# MINI51XAE_v1 register map
File version: 1.0
Registers are 32-bit, read-write, reset 0x0 unless marked. A register's access mark holds for its fields unless they carry their own. Offsets are from the block's base; [hi:lo] are bit positions; {n}, {i} and the like mark numbered series; 'fields as' and 'values as' point back to an identical list.

## PWM — PWM Register Map
Base 0x40040000
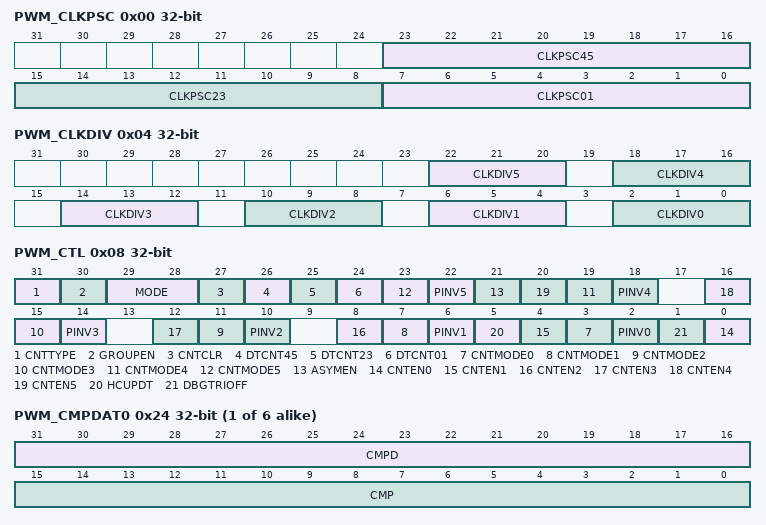
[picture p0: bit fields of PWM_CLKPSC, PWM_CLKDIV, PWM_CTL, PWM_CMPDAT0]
0x00 PWM_CLKPSC — PWM Pre-scale Register
  [23:16] CLKPSC45 — Clock Prescaler 4 For PWM Counter 4 And 5. Clock input is divided by (CLKPSC45 + 1) before it is fed to the corresponding PWM counter.
  [15:8] CLKPSC23 — Clock Prescaler 2 For PWM Counter 2 And 3. Clock input is divided by (CLKPSC23 + 1) before it is fed to the corresponding PWM counter.
  [7:0] CLKPSC01 — Clock Prescaler 0 For PWM Counter 0 And 1. Clock input is divided by (CLKPSC01 + 1) before it is fed to the corresponding PWM counter.
0x04 PWM_CLKDIV — PWM Clock Select Register
  [22:20] CLKDIV5 — Timer 5 Clock Source Selection. Select clock input for PWM timer.
    0=2 clock input/CLKPSC45/2; 1=4 clock input/CLKPSC45/4; 3=8 clock input/CLKPSC45/8; 4=16 clock input/CLKPSC45/16; 5=1 clock input/CLKPSC45/1; 6=Clock input
  [4n+2:4n] CLKDIV{n} (n=0..4) — Timer {n} Clock Source Selection. Select clock input for PWM timer. (Table is the same as CLKDIV5.)
0x08 PWM_CTL — PWM Control Register
  [31] CNTTYPE — PWM Aligned Type Selection Bit
    0=Edge-aligned type; 1=Center-aligned type
  [30] GROUPEN — Group Bit
    0=The signals timing of all PWM channels are independent; 1=Unify the signals timing of PWM0, PWM2 and PWM4 in the same phase which is controlled by PWM0 and also unify the signals timing of PWM1, PWM3 and PWM5 in the same phase which is controlled by PWM1
  [29:28] MODE — PWM Operating Mode Selection
    0=Independent mode; 1=Complementary mode; 2=Synchronized mode
  [27] CNTCLR — Clear PWM Counter Control Bit. Note: It is automatically cleared by hardware.
    0=Do not clear PWM counter; 1=All 16-bit PWM counters cleared to 0x0000
  [26] DTCNT45 — Dead-Zone 4 Generator Enable/Disable (PWM4 And PWM5 Pair For PWM Group). Note: When the dead-zone generator is enabled, the pair of PWM4 and PWM5 becomes a complementary pair for PWM group.
    0=Disabled; 1=Enabled
  [25] DTCNT23 — Dead-Zone 2 Generator Enable/Disable (PWM2 And PWM3 Pair For PWM Group). Note: When the dead-zone generator is enabled, the pair of PWM2 and PWM3 becomes a complementary pair for PWM group.
    0=Disabled; 1=Enabled
  [24] DTCNT01 — Dead-Zone 0 Generator Enable/Disable (PWM0 And PWM1 Pair For PWM Group). Note: When the dead-zone generator is enabled, the pair of PWM0 and PWM1 becomes a complementary pair for PWM group.
    0=Disabled; 1=Enabled
  [4n+3] CNTMODE{n} (n=0..5) — PWM-Timer {n} Auto-Reload/One-Shot Mode. Note: If there is a rising transition at this bit, it will cause PWM_PERIOD{n} and PWM_CMPDAT{n} cleared.
    0=One-shot mode; 1=Auto-reload mode
  [4n+2] PINV{n} (n=0..5) — PWM-Timer {n} Output Inverter Enabled/Disabled
    0=Inverter Disabled; 1=Inverter Enabled
  [21] ASYMEN — Asymmetric Mode In Center-Aligned Type
    0=symmetric mode in center-aligned type; 1=asymmetric mode in center-aligned type
  [4n] CNTEN{n} (n=0..5) — PWM-Timer {n} Enable/Disable Start Run
    0=Corresponding PWM-timer running Stopped; 1=Corresponding PWM-timer start run Enabled
  [5] HCUPDT — Half Cycle Update Enable For Center-Aligned Type
    0=disable half cycle update PERIOD CMP; 1=enable half cycle update PERIOD CMP
  [1] DBGTRIOFF — PWM Debug Mode Configuration Bit (Available In DEBUG Mode Only)
    0=Safe mode: The timer is frozen and PWM outputs are shut down Safe state for the inverter. The timer can still be re-started from where it stops; 1=Normal mode: The timer continues to operate normally May be dangerous in some cases since a constant duty cycle is applied to the inverter (no more interrupts serviced)
{0xC+4i} PWM_PERIOD{i} (i=0..5) — PWM Counter Register {i}
  [15:0] PERIOD — PWM Counter/Timer Loaded Value. PERIOD determines the PWM period. Edge-aligned mode: Note: Any write to PERIOD will take effect in next PWM cycle.
{0x24+4i} PWM_CMPDAT{i} (i=0..5) — PWM Comparator Register {i}
  [31:16] CMPD — PWM Comparator Register For Down Counter In Center-Aligned Asymmetric Mode. Others: PWM output is always high
  [15:0] CMP — PWM Comparator Register. CMP determines the PWM duty. Edge-aligned mode: Note: Any write to CMP will take effect in next PWM cycle.
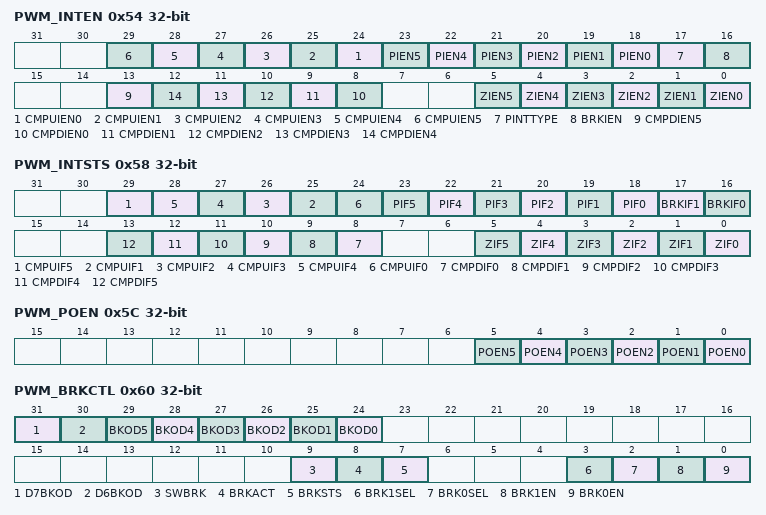
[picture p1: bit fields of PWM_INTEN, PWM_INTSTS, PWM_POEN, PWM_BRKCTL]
0x54 PWM_INTEN — PWM Interrupt Enable Register
  [n+24] CMPUIEN{n} (n=0..5) — PWM Channel {n} Rising Interrupt Enable
    0=Disabled; 1=Enabled
  [n+18] PIEN{n} (n=0..5) — PWM Channel {n} Central Interrupt Enable
    0=Disabled; 1=Enabled
  [17] PINTTYPE — PWM Period Interrupt Type Selection. Note: This bit is effective when PWM in central align mode only.
    0=ZIFn will be set if PWM counter underflows; 1=ZIFn will be set if PWM counter matches PERIODn register
  [16] BRKIEN — Enable Fault Brake0 And 1 Interrupt
    0=Disabling flags BRKIF0 and BRKIF1 to trigger PWM interrupt; 1=Enabling flags BRKIF0 and BRKIF1 can trigger PWM interrupt
  [13] CMPDIEN5 — PWM Channel 5 Duty Interrupt Enable
    0=Disabled. Rising for edge aligned mode. Falling for center aligned mode; 1=Enabled
  [n+8] CMPDIEN{n} (n=0..4) — PWM Channel {n} Duty Interrupt Enable
    0=Disabled; 1=Enabled
  [n] ZIEN{n} (n=0..5) — PWM Channel {n} Period Interrupt Enable
    0=Disabled; 1=Enabled
0x58 PWM_INTSTS — PWM Interrupt Indication Register
  [29] CMPUIF5 — PWM Channel 5 Rise Interrupt Flag. Flag is set by hardware when a channel 5 PWM rise counter reaches. PWM_CNT0. 5. Software can write 1 to clear this bit.
  [n+24] CMPUIF{n} (n=1..4) — PWM Channel {n} Rise Interrupt Flag. Flag is set by hardware when a channel {n} PWM rise counter reaches PWM_CMPDAT{n}. Software can write 1 to clear this bit.
  [24] CMPUIF0 — PWM Channel 1 Rise Interrupt Flag. Flag is set by hardware when a channel 0 PWM rise counter reaches PWM_CMPDAT0. Software can write 1 to clear this bit.
  [n+18] PIF{n} (n=0..5) — PWM Channel {n} Center Interrupt Flag. Flag is set by hardware when a channel {n} PWM rise counter reaches CNT{n}. Software can write 1 to clear this bit.
  [17] BRKIF1 — PWM Brake1 Flag. Note: Software can write 1 to clear this bit.
    0=PWM Brake does not recognize a falling signal at BKP1; 1=When PWM Brake detects a falling signal at pin BKP1, this flag will be set to high
  [16] BRKIF0 — PWM Brake0 Flag. Note: Software can write 1 to clear this bit.
    0=PWM Brake does not recognize a falling signal at BKP0; 1=When PWM Brake detects a falling signal at pin BKP0, this flag will be set to high
  [n+8] CMPDIF{n} (n=0..5) — PWM Channel {n} Duty Interrupt Flag. Flag is set by hardware when a channel {n} PWM counter reaches PWM_CMPDAT{n} in down-count direction. Note: Software can write 1 to clear this bit.
  [n] ZIF{n} (n=0..5) — PWM Channel {n} Period Interrupt Flag. Flag is set by hardware when PWM{n} down counter reaches zero. Note: Software can write 1 to clear this bit.
0x5C PWM_POEN — PWM Output Enable for Channel 0~5
  [n] POEN{n} (n=0..5) — PWM Channel {n} Output Enable Register. Note: The corresponding GPIO pin must be switched to PWM function.
    0=PWM channel {n} output to pin Disabled; 1=PWM channel {n} output to pin Enabled
0x60 PWM_BRKCTL — PWM Fault Brake Control Register
  [31] D7BKOD — D7 Brake Output Select Register
    0=D7 output low when fault brake conditions asserted; 1=D7 output high when fault brake conditions asserted
  [30] D6BKOD — D6 Brake Output Select Register
    0=D6 output low when fault brake conditions asserted; 1=D6 output high when fault brake conditions asserted
  [n+24] BKOD{n} (n=0..5) — PWM Channel {n} Brake Output Select Register
    0=PWM output low when fault brake conditions asserted; 1=PWM output high when fault brake conditions asserted
  [9] SWBRK — Software Brake
    0=Disable PWM Software brake and back to normal PWM function; 1=Assert PWM Brake immediately
  [8] BRKACT — PWM Brake Type
    0=PWM counter stop when brake is asserted; 1=PWM counter keep going when brake is asserted
  [7] BRKSTS — PWM Fault Brake Event Flag (Write 1 Clear). Software can write 1 to clear this bit and must clear this bit before restart PWM counter.
    0=PWM output initial state when fault brake conditions asserted; 1=PWM output fault brake state when fault brake conditions asserted
  [3] BRK1SEL — BKP0 Fault Brake Function Source Selection
    0=EINT0 as one brake source in BKP0; 1=CPO1 as one brake source in BKP0
  [2] BRK0SEL — BKP1 Fault Brake Function Source Selection
    0=EINT1 as one brake source in BKP1; 1=CPO0 as one brake source in BKP1
  [1] BRK1EN — Enable BKP1 Pin Trigger Fault Brake Function 1
    0=Disabling BKP1 pin can trigger brake function 1 (EINT1 or CPO0); 1=Enabling a falling at BKP1 pin can trigger brake function 1
  [0] BRK0EN — Enable BKP0 Pin Trigger Fault Brake Function 0
    0=Disabling BKP0 pin can trigger brake function 0 (EINT0 or CPO1); 1=Enabling a falling at BKP0 pin can trigger brake function 0
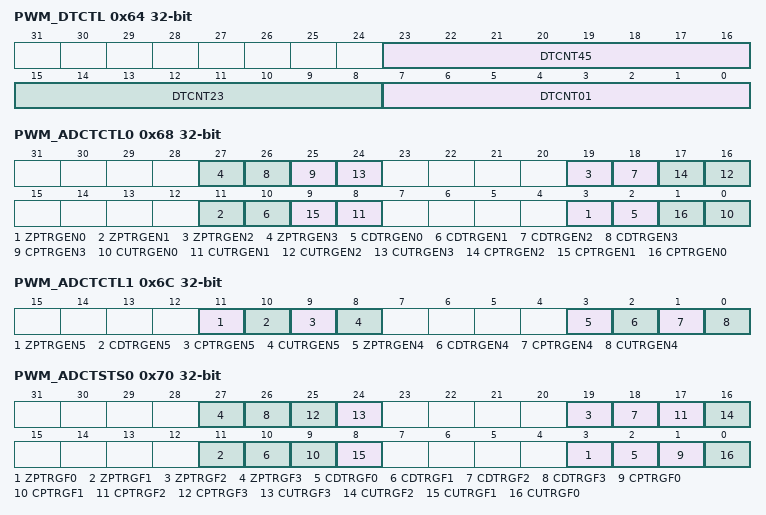
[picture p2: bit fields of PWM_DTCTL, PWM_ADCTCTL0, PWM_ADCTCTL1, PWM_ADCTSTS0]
0x64 PWM_DTCTL — PWM Dead-zone Interval Register
  [23:16] DTCNT45 — Dead-Zone Interval Register For Pair Of Channel4 And Channel5 (PWM4 And PWM5 Pair). These 8 bits determine dead-zone length. The unit time of dead-zone length is received from corresponding CLKDIV bits.
  [15:8] DTCNT23 — Dead-Zone Interval Register For Pair Of Channel2 And Channel3 (PWM2 And PWM3 Pair). These 8 bits determine dead-zone length. The unit time of dead-zone length is received from corresponding CLKDIV bits.
  [7:0] DTCNT01 — Dead-Zone Interval Register For Pair Of Channel0 And Channel1 (PWM0 And PWM1 Pair). These 8 bits determine dead-zone length. The unit time of dead-zone length is received from corresponding CLKDIV bits.
0x68 PWM_ADCTCTL0 — PWM Trigger Control Register 0
  [8n+3] ZPTRGEN{n} (n=0..3) — PWM Channel {n} Zero Point Trigger ADC Enable Bit. Note: This bit is valid for both center aligned mode and edged aligned mode.
    0=Disabled; 1=Enabled
  [8n+2] CDTRGEN{n} (n=0..3) — PWM Channel {n} Compare Down Count Point Trigger ADC Enable Bit. Note: This bit is valid for both center aligned mode and edged aligned mode.
    0=Disabled; 1=Enabled
  [25] CPTRGEN3 — PWM Channel 3 Center Point Trigger ADC Enable Bit. Note: This bit is only valid for PWM in center aligned mode. When PWM is in edged aligned mode, setting this bit is meaningless and will not take any effect.
    0=Disabled; 1=Enabled
  [8n] CUTRGEN{n} (n=0..3) — PWM Channel {n} Compare Up Count Point Trigger ADC Enable Bit. Note: This bit is only valid for PWM in center aligned mode. When PWM is in edged aligned mode, setting this bit is meaningless and will not take any effect.
    0=Disabled; 1=Enabled
  [17] CPTRGEN2 — PWM Channel 2 Center Point Trigger ADC Enable Bit. Note: This bit is only valid for PWM in center aligned mode. When PWM is in edged aligned mode, setting this bit is meaningless and will not take any effect.
    0=Disabled; 1=Enabled
  [9] CPTRGEN1 — Note: This bit is only valid for PWM in center aligned mode. When PWM is in edged aligned mode, setting this bit is meaningless and will not take any effect.
    1=Enabled
  [1] CPTRGEN0 — PWM Channel 0 Center Point Trigger ADC Enable Bit. Note: This bit is only valid for PWM in center aligned mode. When PWM is in edged aligned mode, setting this bit is meaningless and will not take any effect.
    0=Disabled; 1=Enabled
0x6C PWM_ADCTCTL1 — PWM Trigger Control Register 1
  [all] fields
    0=Disabled; 1=Enabled
  [11] ZPTRGEN5 — PWM Channel 5 Zero Point Trigger ADC Enable Bit. Note: This bit is valid for both center aligned mode and edged aligned mode.
  [10] CDTRGEN5 — PWM Channel 5 Compare Down Count Point Trigger ADC Enable Bit. Note: This bit is valid for both center aligned mode and edged aligned mode.
  [9] CPTRGEN5 — PWM Channel 5 Center Point Trigger ADC Enable Bit. Note: This bit is only valid for PWM in center aligned mode. When PWM is in edged aligned mode, setting this bit is meaningless and will not take any effect.
  [8] CUTRGEN5 — PWM Channel 5 Compare Up Count Point Trigger ADC Enable Bit. Note: This bit is only valid for PWM in center aligned mode. When PWM is in edged aligned mode, setting this bit is meaningless and will not take any effect.
  [3] ZPTRGEN4 — PWM Channel 4 Zero Point Trigger ADC Enable Bit. Note: This bit is valid for both center aligned mode and edged aligned mode.
  [2] CDTRGEN4 — PWM Channel 4 Compare Down Count Point Trigger ADC Enable Bit. Note: This bit is valid for both center aligned mode and edged aligned mode.
  [1] CPTRGEN4 — PWM Channel 4 Center Point Trigger ADC Enable Bit. Note: This bit is only valid for PWM in center aligned mode. When PWM is in edged aligned mode, setting this bit is meaningless and will not take any effect.
  [0] CUTRGEN4 — PWM Channel 4 Compare Up Count Point Trigger ADC Enable Bit. Note: This bit is only valid for PWM in center aligned mode. When PWM is in edged aligned mode, setting this bit is meaningless and will not take any effect.
0x70 PWM_ADCTSTS0 — PWM Trigger Status Register 0
  [8n+3] ZPTRGF{n} (n=0..3) — PWM Channel {n} Compare Up Count Point Trigger ADC Flag. Note: Software can write 1 to clear this bit.
  [8n+2] CDTRGF{n} (n=0..3) — PWM Channel {n} Center Point Trigger ADC Flag. Note: Software can write 1 to clear this bit.
  [8n+1] CPTRGF{n} (n=0..3) — PWM Channel {n} Compare Down Count Point Trigger ADC Flag. Note: Software can write 1 to clear this bit.
  [24] CUTRGF3 — PWM Channel 3 Zero Point Trigger ADC Flag. Note: Software can write 1 to clear this bit.
  [16] CUTRGF2 — PWM Channel 3 Zero Point Trigger ADC Flag. Note: Software can write 1 to clear this bit.
  [8] CUTRGF1 — PWM Channel 1 Zero Point Trigger ADC Flag. Note: Software can write 1 to clear this bit.
  [0] CUTRGF0 — PWM Channel 0 Zero Point Trigger ADC Flag. Note: Software can write 1 to clear this bit.
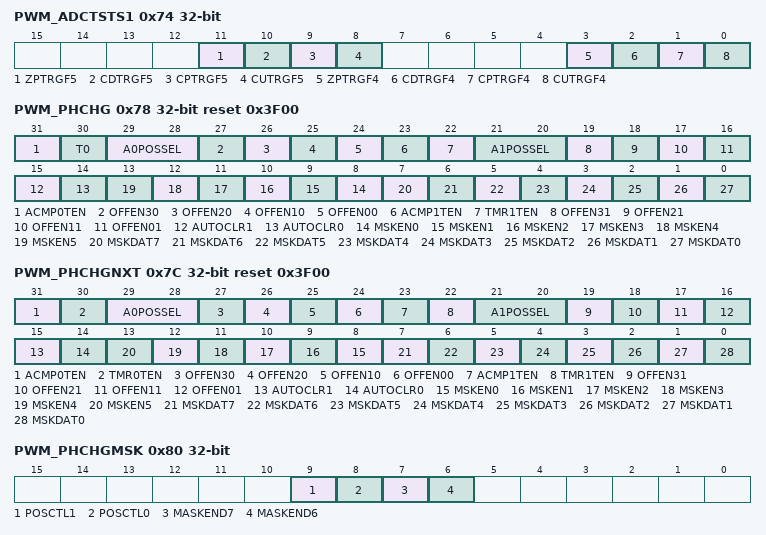
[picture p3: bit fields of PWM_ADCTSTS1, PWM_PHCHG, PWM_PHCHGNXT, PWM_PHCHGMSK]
0x74 PWM_ADCTSTS1 — PWM Trigger Status Register 1
  [11] ZPTRGF5 — PWM Channel 5 Compare Up Count Point Trigger ADC Flag. Note: Software can write 1 to clear this bit.
  [10] CDTRGF5 — PWM Channel 5 Center Point Trigger ADC Flag. Note: Software can write 1 to clear this bit.
  [9] CPTRGF5 — PWM Channel 5 Compare Down Count Point Trigger ADC Flag. Note: Software can write 1 to clear this bit.
  [8] CUTRGF5 — PWM Channel 5 Zero Point Trigger ADC Flag. Note: Software can write 1 to clear this bit.
  [3] ZPTRGF4 — PWM Channel 4 Compare Up Count Point Trigger ADC Flag. Note: Software can write 1 to clear this bit.
  [2] CDTRGF4 — PWM Channel 4 Center Point Trigger ADC Flag. Note: Software can write 1 to clear this bit.
  [1] CPTRGF4 — PWM Channel 4 Compare Down Count Point Trigger ADC Flag. Note: Software can write 1 to clear this bit.
  [0] CUTRGF4 — PWM Channel 4 Zero Point Trigger ADC Flag. Note: Software can write 1 to clear this bit.
0x78 PWM_PHCHG reset 0x3F00 — Phase Changed Register
  [31] ACMP0TEN — Enable ACMP0 Trigger Function. Note: This bit will be auto cleared when ACMP0 trigger PWM if AUTOCLR0 is set.
    0=Disabled; 1=Enabled
  [30] T0 — Enable Timer0 Trigger PWM Function. When this bit is set, timer0 time-out event will update PWM_PHCHG with PWM_PHCHG_NXT register.
    0=Disabled; 1=Enabled
  [29:28] A0POSSEL — A0POSSEL. Select the positive input source of ACMP0.
    0=Select P1.5 as the input of ACMP0; 1=Select P1.0 as the input of ACMP0; 2=Select P1.2 as the input of ACMP0; 3=Select P1.3 as the input of ACMP0
  [27] OFFEN30 — Setting This Bit Will Force MSKEN3 To Output Low Lasting For At Most One Period Cycle As Long As ACMP0 Trigger It; This Feature Is Usually In Step Motor Application. Note: Only for MSKEN0, MSKEN3, MSKEN2, MSKEN3.
    0=Disabled; 1=Enabled
  [26] OFFEN20 — Setting This Bit Will Force MSKEN2 To Output Low Lasting For At Most One Period Cycle As Long As ACMP0 Trigger It; This Feature Is Usually In Step Motor Application. Note: Only for MSKEN0, MSKEN3, MSKEN2, MSKEN3.
    0=Disabled; 1=Enabled
  [25] OFFEN10 — Setting This Bit Will Force MSKEN1 To Output Low Lasting For At Most One Period Cycle As Long As ACMP0 Trigger It; This Feature Is Usually In Step Motor Application. Note: Only for MSKEN0, MSKEN3, MSKEN2, MSKEN3.
    0=Disabled; 1=Enabled
  [24] OFFEN00 — Setting This Bit Will Force MSKEN0 To Output Low Lasting For At Most One Period Cycle As Long As ACMP0 Trigger It; This Feature Is Usually In Step Motor Application. Note: Only for MSKEN0, MSKEN3, MSKEN2, MSKEN3.
    0=Disabled; 1=Enabled
  [23] ACMP1TEN — Enable ACMP1 Trigger Function. Note: This bit will be auto cleared when ACMP1 trigger PWM if AUTOCLR1 is set.
    0=Disabled; 1=Enabled
  [22] TMR1TEN — Enable Timer1 Trigger PWM Function. When this bit is set, timer1 time-out event will update PWM_PHCHG with PWM_PHCHG_NXT register.
    0=Disabled; 1=Enabled
  [21:20] A1POSSEL — A1POSSEL. Select the positive input source of ACMP1.
    0=Select P3.1 as the input of ACMP1; 1=Select P3.2 as the input of ACMP1; 2=Select P3.3 as the input of ACMP1; 3=Select P3.4 as the input of ACMP1
  [19] OFFEN31 — Setting This Bit Will Force MSKEN3 To Output Low Lasting For At Most One Period Cycle As Long As ACMP1 Trigger It; This Feature Is Usually In Step Motor Application. Note: Only for MSKEN0, MSKEN3, MSKEN2, MSKEN3.
    0=Disabled; 1=Enabled
  [18] OFFEN21 — Setting This Bit Will Force MSKEN2 To Output Low Lasting For At Most One Period Cycle As Long As ACMP1 Trigger It; This Feature Is Usually In Step Motor Application. Note: Only for MSKEN0, MSKEN3, MSKEN2, MSKEN3.
    0=Disabled; 1=Enabled
  [17] OFFEN11 — Setting This Bit Will Force MSKEN1 To Output Low Lasting For At Most One Period Cycle As Long As ACMP1 Trigger It; This Feature Is Usually In Step Motor Application. Note: Only for MSKEN0, MSKEN3, MSKEN2, MSKEN3.
    0=Disabled; 1=Enabled
  [16] OFFEN01 — Setting This Bit Will Force MSKEN0 To Output Low Lasting For At Most One Period Cycle As Long As ACMP1 Trigger It; This Feature Is Usually In Step Motor Application. Note: only for MSKEN0, MSKEN3, MSKEN2, MSKEN3.
    0=Disabled; 1=Enabled
  [15] AUTOCLR1 — Hardware Auto Clear ACMP1TEN When ACMP1 Trigger It
    0=Enabled; 1=Disabled
  [14] AUTOCLR0 — Hardware Auto Clear ACMP0TEN When ACMP0 Trigger It
    0=Enabled; 1=Disabled
  [n+8] MSKEN{n} (n=0..5) — MSKEN Channel {n} Output Enable Control
    0=Output MSKDAT{n} specified in bit {n} of PWM_PHCHG register; 1=Output the original channel {n} waveform
  [7] MSKDAT7 — MSKDAT7: When MSKEN7 Is 1, Channel 7's Output Waveform Is MSKDAT7
    0=Output low; 1=Output high
  [6] MSKDAT6 — MSKDAT6: When MSKEN6 Is 1, Channel 6's Output Waveform Is MSKDAT6
    0=Output low; 1=Output high
  [5] MSKDAT5 — MSKDAT5: When MSKEN5 Is Zero, Channel 5's Output Waveform Is MSKDAT5
    0=Output low; 1=Output high
  [4] MSKDAT4 — MSKDAT4: When MSKEN4is Zero, Channel 4's Output Waveform Is MSKDAT4
    0=Output low; 1=Output high
  [3] MSKDAT3 — MSKDAT3: When MSKEN3 Is Zero, Channel 3's Output Waveform Is MSKDAT3
    0=Output low; 1=Output high
  [2] MSKDAT2 — MSKDAT2: When MSKEN2 Is Zero, Channel 2's Output Waveform Is MSKDAT2
    0=Output low; 1=Output high
  [1] MSKDAT1 — MSKDAT1: When MSKEN1is Zero, Channel 1's Output Waveform Is MSKDAT1
    0=Output low; 1=Output high
  [0] MSKDAT0 — MSKDAT0: When MSKEN0 Is Zero, Channel 0's Output Waveform Is MSKDAT0
    0=Output low; 1=Output high
0x7C PWM_PHCHGNXT reset 0x3F00 — Next Phase Change Register
  [31] ACMP0TEN — Enable ACMP0 Trigger Function. Note: This bit will be auto cleared when ACMP0 trigger PWM if AUTOCLR0 is set.
    0=Disabled; 1=Enabled
  [30] TMR0TEN — Enable Timer0 Trigger PWM Function. When this bit is set, timer0 time-out event will update PWM_PHCHG with PWM_PHCHG_NXT register.
    0=Disabled; 1=Enabled
  [29:28] A0POSSEL — A0POSSEL. Select the positive input source of ACMP0.
    values as PWM_PHCHG.A0POSSEL
  [27] OFFEN30 — Setting This Bit Will Force MSKEN3 To Output Low Lasting For At Most One Period Cycle As Long As ACMP0 Trigger It; This Feature Is Usually In Step Motor Application. Note: Only for MSKEN0, MSKEN3, MSKEN2, MSKEN3.
    0=Disabled; 1=Enabled
  [26] OFFEN20 — Setting This Bit Will Force MSKEN2 To Output Low Lasting For At Most One Period Cycle As Long As ACMP0 Trigger It; This Feature Is Usually In Step Motor Application. Note: Only for MSKEN0, MSKEN3, MSKEN2, MSKEN3..
    0=Disabled; 1=Enabled
  [25] OFFEN10 — Setting This Bit Will Force MSKEN1 To Output Low Lasting For At Most One Period Cycle As Long As ACMP0 Trigger It; This Feature Is Usually In Step Motor Application. Note: Only for MSKEN0, MSKEN3, MSKEN2, MSKEN3.
    0=Disabled; 1=Enabled
  [24] OFFEN00 — Setting This Bit Will Force MSKEN0 To Output Low Lasting For At Most One Period Cycle As Long As ACMP0 Trigger It; This Feature Is Usually In Step Motor Application. Note: Only for MSKEN0, MSKEN3, MSKEN2, MSKEN3.
    0=Disabled; 1=Enabled
  [23] ACMP1TEN — Enable ACMP1 Trigger Function. Note: This bit will be auto cleared when ACMP1 trigger PWM if AUTOCLR1 is set.
    0=Disabled; 1=Enabled
  [22] TMR1TEN — Enable Timer1 Trigger PWM Function. When this bit is set, timer1 time-out event will update PWM_PHCHG with PWM_PHCHG_NXT register.
    0=Disabled; 1=Enabled
  [21:20] A1POSSEL — A1POSSEL. Select the positive input source of ACMP1.
    values as PWM_PHCHG.A1POSSEL
  [19] OFFEN31 — Setting This Bit Will Force MSKEN3to Output Low Lasting For At Most One Period Cycle As Long As ACMP1 Trigger It; This Feature Is Usually In Step Motor Application. Note: Only for MSKEN0, MSKEN3, MSKEN2, MSKEN3.
    0=Disabled; 1=Enabled
  [18] OFFEN21 — Setting This Bit Will Force MSKEN2 To Output Low Lasting For At Most One Period Cycle As Long As ACMP1 Trigger It; This Feature Is Usually In Step Motor Application. Note: Only for MSKEN0, MSKEN3, MSKEN2, MSKEN3.
    0=Disabled; 1=Enabled
  [17] OFFEN11 — Setting This Bit Will Force MSKEN1 To Output Low Lasting For At Most One Period Cycle As Long As ACMP1 Trigger It; This Feature Is Usually In Step Motor Application. Note: Only for MSKEN0, MSKEN3, MSKEN2, MSKEN3.
    0=Disabled; 1=Enabled
  [16] OFFEN01 — Setting This Bit Will Force MSKEN0 To Output Low Lasting For At Most One Period Cycle As Long As ACMP1 Trigger It; This Feature Is Usually In Step Motor Application. Note: only for MSKEN0, MSKEN3, MSKEN2, MSKEN3.
    0=Disabled; 1=Enabled
  [15] AUTOCLR1 — Hardware Auto Clear ACMP1TEN When ACMP1 Trigger It
    0=Enabled; 1=Disabled
  [14] AUTOCLR0 — Hardware Auto Clear ACMP0TEN When ACMP0 Trigger It
    0=Enabled; 1=Disabled
  [n+8] MSKEN{n} (n=0..5) — MSKEN Channel {n} Output Enable Control
    values as PWM_PHCHG.MSKEN0
  [7] MSKDAT7 — MSKDAT7: When MSKEN7 Is 1, Channel 7's Output Waveform Is MSKDAT7
    0=Output low; 1=Output high
  [6] MSKDAT6 — MSKDAT6: When MSKEN6 Is 1, Channel 6's Output Waveform Is MSKDAT6
    0=Output low; 1=Output high
  [5] MSKDAT5 — MSKDAT5: When MSKEN5 Is Zero, Channel 5's Output Waveform Is MSKDAT5
    0=Output low; 1=Output high
  [4] MSKDAT4 — MSKDAT4: When MSKEN4is Zero, Channel 4's Output Waveform Is MSKDAT4
    0=Output low; 1=Output high
  [3] MSKDAT3 — MSKDAT3: When MSKEN3 Is Zero, Channel 3's Output Waveform Is MSKDAT3
    0=Output low; 1=Output high
  [2] MSKDAT2 — MSKDAT2: When MSKEN2 Is Zero, Channel 2's Output Waveform Is MSKDAT2
    0=Output low; 1=Output high
  [1] MSKDAT1 — MSKDAT1: When MSKEN1is Zero, Channel 1's Output Waveform Is MSKDAT1
    0=Output low; 1=Output high
  [0] MSKDAT0 — MSKDAT0: When MSKEN0 Is Zero, Channel 0's Output Waveform Is MSKDAT0
    0=Output low; 1=Output high
0x80 PWM_PHCHGMSK — Phase Change MASK Register
  [9] POSCTL1 — ACMP1 Positive Input Selection Control. Note: Register CMP1CR is describe in Comparator Controller chapter
    0=The input of ACMP1 is controlled by CMP1CR; 1=The input of ACMP1 is controlled by A1POSSEL of PWM_PHCHG register
  [8] POSCTL0 — ACMP0 Positive Input Selection Control. Note: Register CMP0CR is describe in Comparator Controller chapter
    0=The input of ACMP0 is controlled by CMP0CR; 1=The input of ACMP0 is controlled by A0POSSEL of PWM_PHCHG register
  [7] MASKEND7 — MASK For D7
    0=Original GPIO P0.0; 1=D7
  [6] MASKEND6 — MASK For D6
    0=Original GPIO P0.1; 1=D6
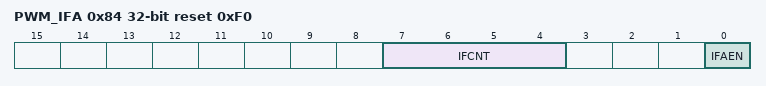
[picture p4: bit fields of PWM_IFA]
0x84 PWM_IFA reset 0xF0 — Period Interrupt Accumulation Control Register
  [7:4] IFCNT — Interrupt Accumulation Count. When IFCNT is set, IFCNT will decrease when every ZIF0 flag is set and when IFCNT reach to zero, the PWM0 interrupt will occurred and IFCNT will reload itself.
  [0] IFAEN — Interrupt Accumulation Enable
    0=Disabled; 1=Enabled
